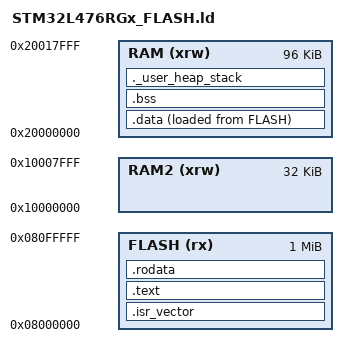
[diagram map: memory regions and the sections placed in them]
/*
 * Linker script for the STM32L476RG
 * 1024K Flash, 128K SRAM
 */

/* Entry Point */
ENTRY(Reset_Handler)

/* Memory Regions */
MEMORY
{
  FLASH (rx)      : ORIGIN = 0x08000000, LENGTH = 1024K
  RAM (xrw)       : ORIGIN = 0x20000000, LENGTH = 96K
  RAM2 (xrw)      : ORIGIN = 0x10000000, LENGTH = 32K /* Not contiguous with RAM */
}

/* Highest address of the stack */
_estack = ORIGIN(RAM) + LENGTH(RAM);

/* Minimum stack and heap sizes */
_Min_Stack_Size = 0x400; /* 1 KB */
_Min_Heap_Size  = 0x200; /* 0.5 KB */

/* Sections */
SECTIONS
{
  /* The startup code goes first in Flash */
  .isr_vector :
  {
    . = ALIGN(4);
    KEEP(*(.isr_vector)) /* Startup code */
    . = ALIGN(4);
  } >FLASH

  /* The program code and other data */
  .text :
  {
    . = ALIGN(4);
    *(.text)           /* .text sections (code) */
    *(.text*)          /* .text* sections (code) */
    *(.glue_7)         /* glue arm to thumb */
    *(.glue_7t)        /* glue thumb to arm */
    *(.eh_frame)
    KEEP (*(.init))
    KEEP (*(.fini))
    . = ALIGN(4);
    _etext = .;        /* define a global symbols at end of code */
  } >FLASH

  /* Read-only data */
  .rodata :
  {
    . = ALIGN(4);
    *(.rodata)
    *(.rodata*)
    . = ALIGN(4);
  } >FLASH

  /* This is the symbol the startup code needs to find the initial values for .data */
  _sidata = LOADADDR(.data);

  /* Initialized data section */
  .data :
  {
    . = ALIGN(4);
    _sdata = .;        /* create a global symbol at data start */
    *(.data)           /* .data sections */
    *(.data*)          /* .data* sections */
    . = ALIGN(4);
    _edata = .;        /* define a global symbol at data end */
  } >RAM AT> FLASH

  /* Uninitialized data section (BSS) */
  .bss :
  {
    . = ALIGN(4);
    _sbss = .;         /* define a global symbol at bss start */
    __bss_start__ = _sbss;
    *(.bss)
    *(.bss*)
    *(COMMON)
    . = ALIGN(4);
    _ebss = .;         /* define a global symbol at bss end */
    __bss_end__ = _ebss;
  } >RAM

  /* User_heap_stack section, used to check that there is enough RAM left */
  ._user_heap_stack :
  {
    . = ALIGN(8);
    PROVIDE ( end = . );
    PROVIDE ( _end = . );
    . = . + _Min_Heap_Size;
    . = . + _Min_Stack_Size;
    . = ALIGN(8);
  } >RAM

  /DISCARD/ :
  {
    libc.a ( * )
    libm.a ( * )
    libgcc.a ( * )
  }
}
